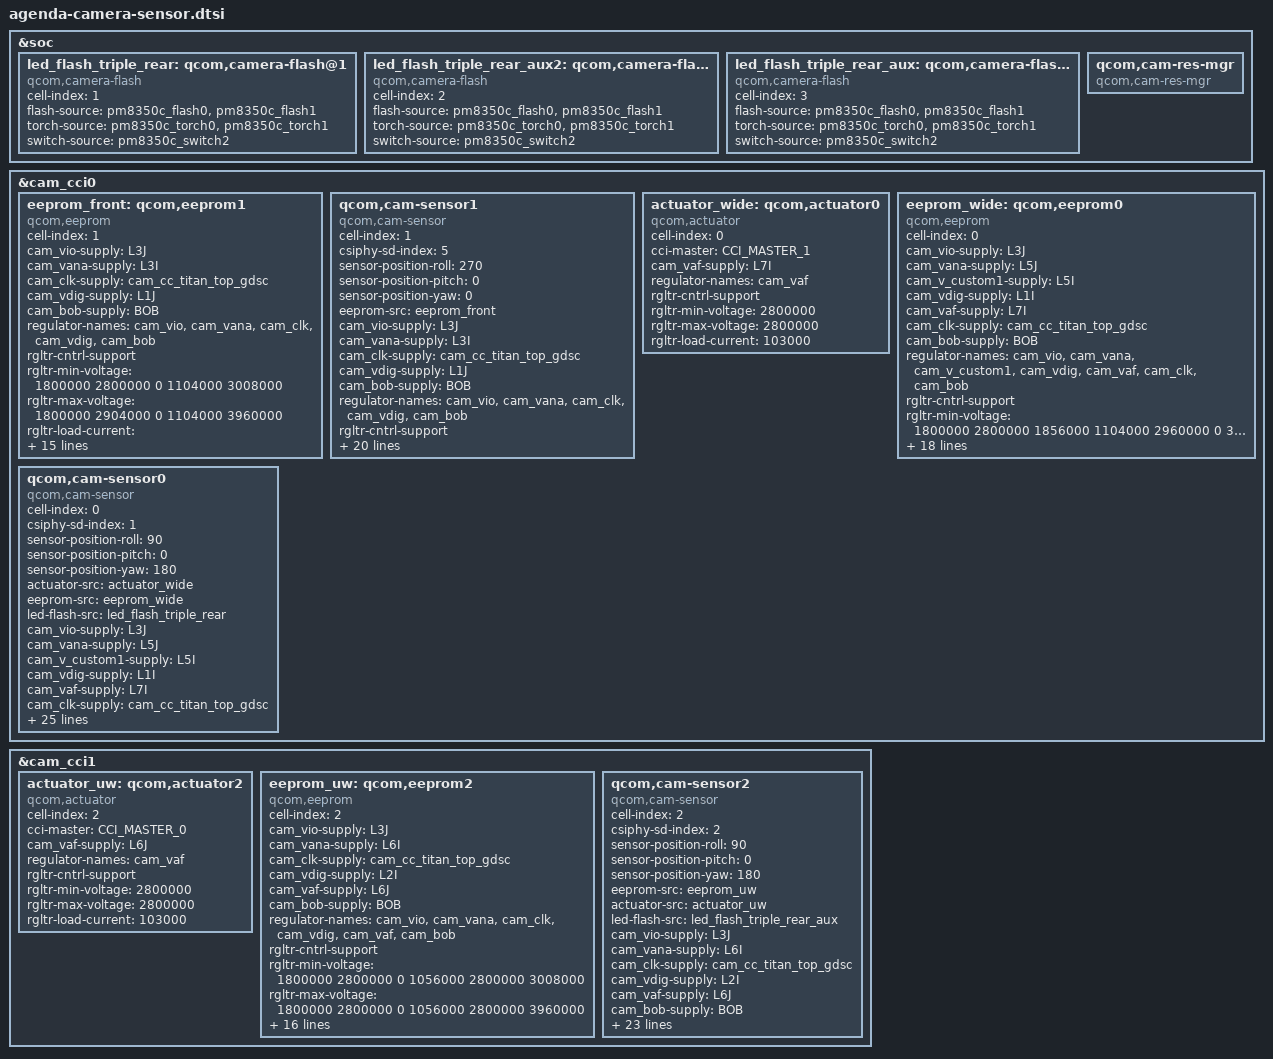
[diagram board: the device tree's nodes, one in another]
#include <dt-bindings/clock/qcom,camcc-waipio.h>
#include <dt-bindings/msm-camera.h>

&soc {
	led_flash_triple_rear: qcom,camera-flash@1 {
		cell-index = <1>;
		compatible = "qcom,camera-flash";
		flash-source = <&pm8350c_flash0 &pm8350c_flash1>;
		torch-source = <&pm8350c_torch0 &pm8350c_torch1>;
		switch-source = <&pm8350c_switch2>;
		status = "ok";
	};

	led_flash_triple_rear_aux2: qcom,camera-flash@2 {
		cell-index = <2>;
		compatible = "qcom,camera-flash";
		flash-source = <&pm8350c_flash0 &pm8350c_flash1>;
		torch-source = <&pm8350c_torch0 &pm8350c_torch1>;
		switch-source = <&pm8350c_switch2>;
		status = "ok";
	};

	led_flash_triple_rear_aux: qcom,camera-flash@3 {
		cell-index = <3>;
		compatible = "qcom,camera-flash";
		flash-source = <&pm8350c_flash0 &pm8350c_flash1>;
		torch-source = <&pm8350c_torch0 &pm8350c_torch1>;
		switch-source = <&pm8350c_switch2>;
		status = "ok";
	};

	qcom,cam-res-mgr {
		compatible = "qcom,cam-res-mgr";
		status = "ok";
	};
};

&cam_cci0 {
	eeprom_front: qcom,eeprom1 {
		cell-index = <1>;
		compatible = "qcom,eeprom";
		cam_vio-supply = <&L3J>;
		cam_vana-supply = <&L3I>;
		cam_clk-supply = <&cam_cc_titan_top_gdsc>;
		cam_vdig-supply = <&L1J>;
		cam_bob-supply = <&BOB>;
		regulator-names = "cam_vio", "cam_vana", "cam_clk", "cam_vdig",
			"cam_bob";
		rgltr-cntrl-support;
		rgltr-min-voltage = <1800000 2800000 0 1104000 3008000>;
		rgltr-max-voltage = <1800000 2904000 0 1104000 3960000>;
		rgltr-load-current = <10000 14720 0 30000 7070000>;
		gpio-no-mux = <0>;
		pinctrl-names = "cam_default", "cam_suspend";
		pinctrl-0 = <&cam_sensor_mclk5_active
				 &cam_sensor_active_rst5>;
		pinctrl-1 = <&cam_sensor_mclk5_suspend
				 &cam_sensor_suspend_rst5>;
		gpios = <&tlmm 105 0>,
			<&tlmm 118 0>;
		gpio-reset = <1>;
		gpio-req-tbl-num = <0 1>;
		gpio-req-tbl-flags = <1 0>;
		gpio-req-tbl-label = "CAMIF_MCLK5",
					"CAM_RESET5";
		cci-master = <CCI_MASTER_0>;
		clocks = <&clock_camcc CAM_CC_MCLK5_CLK>;
		clock-names = "cam_clk";
		clock-cntl-level = "nominal";
		clock-rates = <19200000>;
		status = "ok";
	};

	qcom,cam-sensor1 {
		cell-index = <1>;
		compatible = "qcom,cam-sensor";
		csiphy-sd-index = <5>;
		sensor-position-roll = <270>;
		sensor-position-pitch = <0>;
		sensor-position-yaw = <0>;
		eeprom-src = <&eeprom_front>;
		cam_vio-supply = <&L3J>;
		cam_vana-supply = <&L3I>;
		cam_clk-supply = <&cam_cc_titan_top_gdsc>;
		cam_vdig-supply = <&L1J>;
		cam_bob-supply = <&BOB>;
		regulator-names = "cam_vio", "cam_vana", "cam_clk", "cam_vdig",
			"cam_bob";
		rgltr-cntrl-support;
		rgltr-min-voltage = <1800000 2800000 0 1104000 3008000>;
		rgltr-max-voltage = <1800000 2904000 0 1104000 3960000>;
		rgltr-load-current = <10000 14720 0 30000 7070000>;
		gpio-no-mux = <0>;
		pinctrl-names = "cam_default", "cam_suspend";
		pinctrl-0 = <&cam_sensor_mclk5_active
				 &cam_sensor_active_rst5>;
		pinctrl-1 = <&cam_sensor_mclk5_suspend
				 &cam_sensor_suspend_rst5>;
		gpios = <&tlmm 105 0>,
			<&tlmm 118 0>;
		gpio-reset = <1>;
		gpio-req-tbl-num = <0 1>;
		gpio-req-tbl-flags = <1 0>;
		gpio-req-tbl-label = "CAMIF_MCLK5",
					"CAM_RESET5";
		cci-master = <CCI_MASTER_0>;
		clocks = <&clock_camcc CAM_CC_MCLK5_CLK>;
		clock-names = "cam_clk";
		clock-cntl-level = "nominal";
		clock-rates = <19200000>;
		status = "ok";
	};

	actuator_wide: qcom,actuator0 {
		cell-index = <0>;
		compatible = "qcom,actuator";
		cci-master = <CCI_MASTER_1>;
		cam_vaf-supply = <&L7I>;
		regulator-names = "cam_vaf";
		rgltr-cntrl-support;
		rgltr-min-voltage = <2800000>;
		rgltr-max-voltage = <2800000>;
		rgltr-load-current = <103000>;
		status = "ok";
	};

	eeprom_wide: qcom,eeprom0 {
		cell-index = <0>;
		compatible = "qcom,eeprom";
		cam_vio-supply = <&L3J>;
		cam_vana-supply = <&L5J>;
		cam_v_custom1-supply = <&L5I>;
		cam_vdig-supply = <&L1I>;
		cam_vaf-supply = <&L7I>;
		cam_clk-supply = <&cam_cc_titan_top_gdsc>;
		cam_bob-supply = <&BOB>;
		regulator-names = "cam_vio", "cam_vana", "cam_v_custom1",
			"cam_vdig", "cam_vaf", "cam_clk", "cam_bob";
		rgltr-cntrl-support;
		rgltr-min-voltage = <1800000 2800000 1856000 1104000 2960000 0 3008000>;
		rgltr-max-voltage = <1800000 2800000 1856000 1104000 2960000 0 3960000>;
		rgltr-load-current = <10000 139300 90100 872000 103000 0 7070000>;
		gpio-no-mux = <0>;
		pinctrl-names = "cam_default", "cam_suspend";
		pinctrl-0 = <&cam_sensor_mclk1_active
				 &cam_sensor_active_rst1>;
		pinctrl-1 = <&cam_sensor_mclk1_suspend
				 &cam_sensor_suspend_rst1>;
		gpios = <&tlmm 101 0>,
			<&tlmm 24 0>;
		gpio-reset = <1>;
		gpio-req-tbl-num = <0 1>;
		gpio-req-tbl-flags = <1 0>;
		gpio-req-tbl-label = "CAMIF_MCLK1",
					"CAM_RESET1";
		cci-master = <CCI_MASTER_1>;
		clocks = <&clock_camcc CAM_CC_MCLK1_CLK>;
		clock-names = "cam_clk";
		clock-cntl-level = "nominal";
		clock-rates = <19200000>;
		status = "ok";
	};

	qcom,cam-sensor0 {
		cell-index = <0>;
		compatible = "qcom,cam-sensor";
		csiphy-sd-index = <1>;
		sensor-position-roll = <90>;
		sensor-position-pitch = <0>;
		sensor-position-yaw = <180>;
		actuator-src = <&actuator_wide>;
		eeprom-src = <&eeprom_wide>;
                led-flash-src = <&led_flash_triple_rear>;
		cam_vio-supply = <&L3J>;
		cam_vana-supply = <&L5J>;
		cam_v_custom1-supply = <&L5I>;
		cam_vdig-supply = <&L1I>;
		cam_vaf-supply = <&L7I>;
		cam_clk-supply = <&cam_cc_titan_top_gdsc>;
		cam_bob-supply = <&BOB>;
		regulator-names = "cam_vio", "cam_vana", "cam_v_custom1",
			"cam_vdig", "cam_vaf", "cam_clk", "cam_bob";
		rgltr-cntrl-support;
		rgltr-min-voltage = <1800000 2800000 1780000 1104000 2800000 0 3008000>;
		rgltr-max-voltage = <1800000 2800000 1780000 1104000 2800000 0 3960000>;
		rgltr-load-current = <10000 139300 90100 872000 103000 0 7070000>;
		gpio-no-mux = <0>;
		pinctrl-names = "cam_default", "cam_suspend";
		pinctrl-0 = <&cam_sensor_mclk1_active
				 &cam_sensor_active_rst1>;
		pinctrl-1 = <&cam_sensor_mclk1_suspend
				 &cam_sensor_suspend_rst1>;
		gpios = <&tlmm 101 0>,
			<&tlmm 24 0>;
		gpio-reset = <1>;
		gpio-req-tbl-num = <0 1>;
		gpio-req-tbl-flags = <1 0>;
		gpio-req-tbl-label = "CAMIF_MCLK1",
					"CAM_RESET1";
		cci-master = <CCI_MASTER_1>;
		clocks = <&clock_camcc CAM_CC_MCLK1_CLK>;
		clock-names = "cam_clk";
		clock-cntl-level = "nominal";
		clock-rates = <19200000>;
		status = "ok";
	};
};

&cam_cci1 {
	actuator_uw: qcom,actuator2 {
		cell-index = <2>;
		compatible = "qcom,actuator";
		cci-master = <CCI_MASTER_0>;
		cam_vaf-supply = <&L6J>;
		regulator-names = "cam_vaf";
		rgltr-cntrl-support;
		rgltr-min-voltage = <2800000>;
		rgltr-max-voltage = <2800000>;
		rgltr-load-current = <103000>;
		status = "ok";
	};

	eeprom_uw: qcom,eeprom2 {
		cell-index = <2>;
		compatible = "qcom,eeprom";
		cam_vio-supply = <&L3J>;
		cam_vana-supply = <&L6I>;
		cam_clk-supply = <&cam_cc_titan_top_gdsc>;
		cam_vdig-supply = <&L2I>;
		cam_vaf-supply = <&L6J>;
		cam_bob-supply = <&BOB>;
		regulator-names = "cam_vio", "cam_vana", "cam_clk", "cam_vdig",
			"cam_vaf", "cam_bob";
		rgltr-cntrl-support;
		rgltr-min-voltage = <1800000 2800000 0 1056000 2800000 3008000>;
		rgltr-max-voltage = <1800000 2800000 0 1056000 2800000 3960000>;
		rgltr-load-current = <10000 14720 0 30000 10000 7070000>;
		gpio-no-mux = <0>;
		pinctrl-names = "cam_default", "cam_suspend";
		pinctrl-0 = <&cam_sensor_mclk2_active
				&cam_sensor_active_rst2>;
		pinctrl-1 = <&cam_sensor_mclk2_suspend
				&cam_sensor_suspend_rst2>;
		gpios = <&tlmm 102 0>,
			<&tlmm 117 0>;
		gpio-reset = <1>;
		gpio-req-tbl-num = <0 1>;
		gpio-req-tbl-flags = <1 0>;
		gpio-req-tbl-label = "CAMIF_MCLK2",
					"CAM_RESET2";
		cci-master = <CCI_MASTER_0>;
		clocks = <&clock_camcc CAM_CC_MCLK2_CLK>;
		clock-names = "cam_clk";
		clock-cntl-level = "nominal";
		clock-rates = <19200000>;
		status = "ok";
	};

	qcom,cam-sensor2 {
		cell-index = <2>;
		compatible = "qcom,cam-sensor";
		csiphy-sd-index = <2>;
		sensor-position-roll = <90>;
		sensor-position-pitch = <0>;
		sensor-position-yaw = <180>;
		eeprom-src = <&eeprom_uw>;
		actuator-src = <&actuator_uw>;
                led-flash-src = <&led_flash_triple_rear_aux>;
		cam_vio-supply = <&L3J>;
		cam_vana-supply = <&L6I>;
		cam_clk-supply = <&cam_cc_titan_top_gdsc>;
		cam_vdig-supply = <&L2I>;
		cam_vaf-supply = <&L6J>;
		cam_bob-supply = <&BOB>;
		regulator-names = "cam_vio", "cam_vana", "cam_clk", "cam_vdig",
			"cam_vaf", "cam_bob";
		rgltr-cntrl-support;
		rgltr-min-voltage = <1800000 2800000 0 1056000 2800000 3008000>;
		rgltr-max-voltage = <1800000 2800000 0 1056000 2800000 3960000>;
		rgltr-load-current = <10000 14720 0 30000 10000 7070000>;
		gpio-no-mux = <0>;
		pinctrl-names = "cam_default", "cam_suspend";
		pinctrl-0 = <&cam_sensor_mclk2_active
				&cam_sensor_active_rst2>;
		pinctrl-1 = <&cam_sensor_mclk2_suspend
				&cam_sensor_suspend_rst2>;
		gpios = <&tlmm 102 0>,
			<&tlmm 117 0>;
		gpio-reset = <1>;
		gpio-req-tbl-num = <0 1>;
		gpio-req-tbl-flags = <1 0>;
		gpio-req-tbl-label = "CAMIF_MCLK2",
					"CAM_RESET2";
		cci-master = <CCI_MASTER_0>;
		clocks = <&clock_camcc CAM_CC_MCLK2_CLK>;
		clock-names = "cam_clk";
		clock-cntl-level = "nominal";
		clock-rates = <19200000>;
		status = "ok";
	};
};
